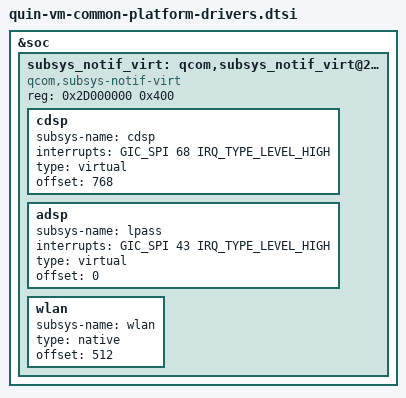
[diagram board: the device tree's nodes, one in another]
#include <dt-bindings/interrupt-controller/arm-gic.h>

&soc {
	subsys_notif_virt: qcom,subsys_notif_virt@2D000000 {
		compatible = "qcom,subsys-notif-virt";
		reg = <0x2D000000 0x400>;
		reg-names = "vdev_base";
		cdsp {
			subsys-name = "cdsp";
			interrupts = <GIC_SPI 68 IRQ_TYPE_LEVEL_HIGH>;
			interrupt-names = "state-irq";
			type = "virtual";
			offset = <768>;
		};

		adsp {
			subsys-name = "lpass";
			interrupts = <GIC_SPI 43 IRQ_TYPE_LEVEL_HIGH>;
			interrupt-names = "state-irq";
			type = "virtual";
			offset = <0>;
		};

		wlan {
			subsys-name = "wlan";
			type = "native";
			offset = <512>;
		};
	};
};
